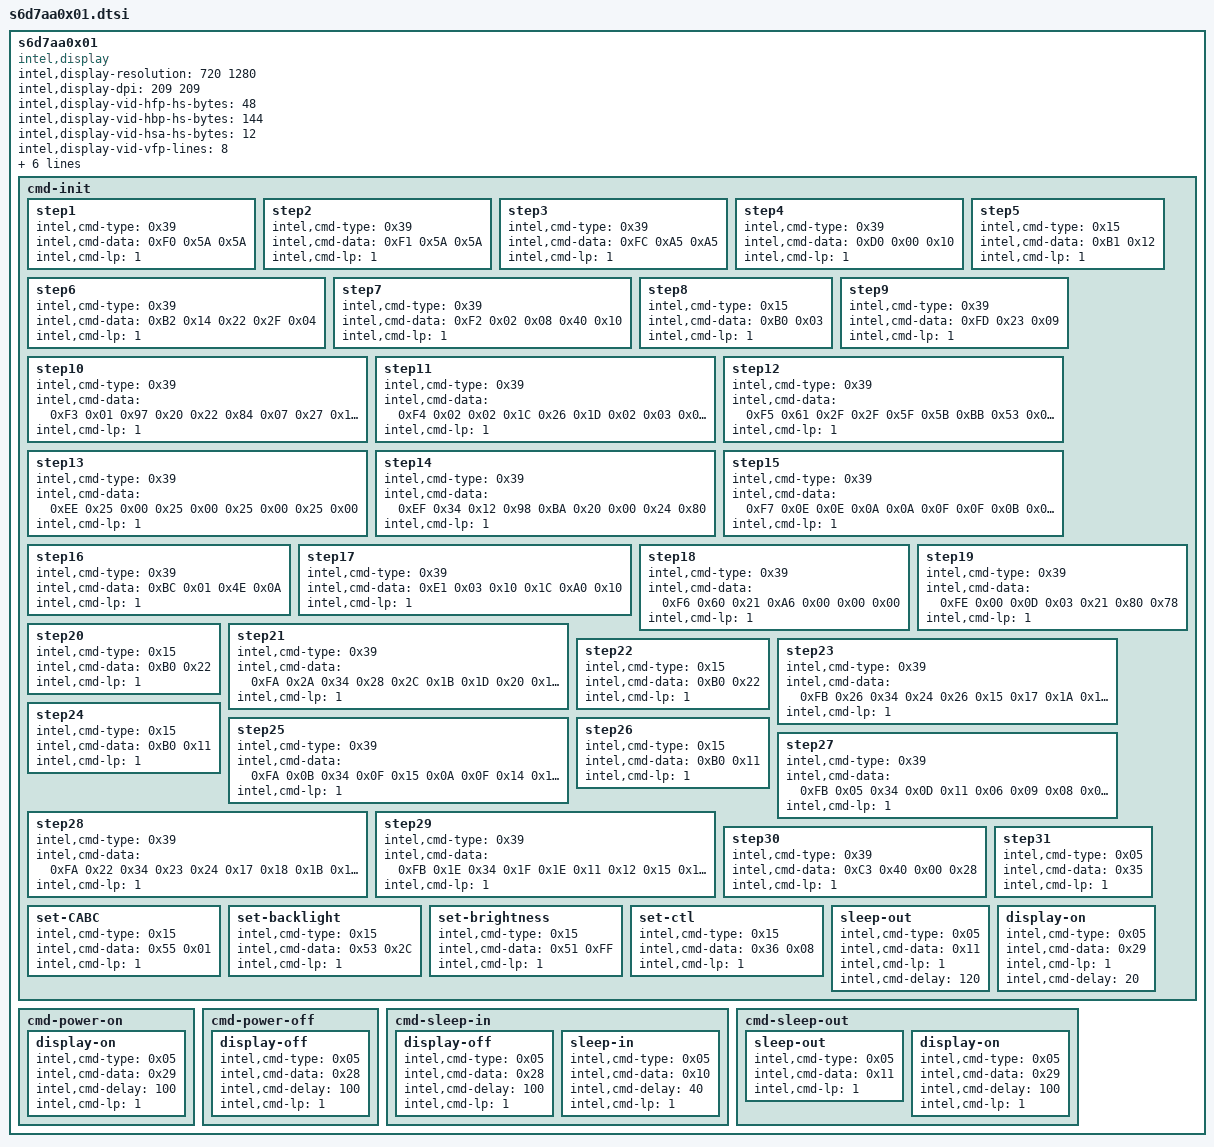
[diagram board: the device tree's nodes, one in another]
s6d7aa0x01{
		compatible = "intel,display";
		intel,display-resolution= <720 1280>;
		intel,display-dpi= <209 209>;

		/* MIPI-DSI video mode settings */
		intel,display-vid-hfp-hs-bytes = <48>;
		intel,display-vid-hbp-hs-bytes = <144>;
		intel,display-vid-hsa-hs-bytes = <12>;
		intel,display-vid-vfp-lines = <8>;
		intel,display-vid-vbp-lines = <4>;
		intel,display-vid-vsa-lines = <4>;

		intel,display-vid-mode = "burst";
		intel,display-vid-id = <0>;
		intel,display-vid-pixel = "24packed";

		intel,display-reset = <1 2 0 1 1 20>;

		cmd-init {
			step1 {
				intel,cmd-type = <0x39>;
				intel,cmd-data = <0xF0 0x5A 0x5A>;
				intel,cmd-lp = <1>;
			};
			step2{
				intel,cmd-type = <0x39>;
				intel,cmd-data = <0xF1 0x5A 0x5A>;
				intel,cmd-lp = <1>;
			};
			step3 {
				intel,cmd-type = <0x39>;
				intel,cmd-data = <0xFC 0xA5 0xA5>;
				intel,cmd-lp = <1>;
			};
			step4 {
				intel,cmd-type = <0x39>;
				intel,cmd-data = <0xD0 0x00 0x10>;
				intel,cmd-lp = <1>;
			};
			step5 {
				intel,cmd-type = <0x15>;
				intel,cmd-data = <0xB1 0x12>;
				intel,cmd-lp = <1>;
			};
			step6 {
				intel,cmd-type = <0x39>;
				intel,cmd-data = <0xB2 0x14 0x22 0x2F 0x04>;
				intel,cmd-lp = <1>;
			};
			step7 {
				intel,cmd-type = <0x39>;
				intel,cmd-data = <0xF2 0x02 0x08 0x40 0x10>;
				intel,cmd-lp = <1>;
			};
			step8 {
				intel,cmd-type = <0x15>;
				intel,cmd-data = <0xB0 0x03>;
				intel,cmd-lp = <1>;
			};
			step9 {
				intel,cmd-type = <0x39>;
				intel,cmd-data = <0xFD 0x23 0x09>;
				intel,cmd-lp = <1>;
			};
			step10 {
				intel,cmd-type = <0x39>;
				intel,cmd-data = <0xF3 0x01 0x97 0x20 0x22 0x84 0x07 0x27 0x10 0x26 0x00>;
				intel,cmd-lp = <1>;
			};
			step11 {
				intel,cmd-type = <0x39>;
				intel,cmd-data = <0xF4 0x02 0x02 0x1C 0x26 0x1D 0x02 0x03 0x03 0x03 0x1C 0x01C 0x03 0x00 0x0C 0x0C 0x03 0x02 0x03 0x06 0x06 0x13 0x14 0x01 0x15 0x01 0x04 0x02 0x61 0x78 0x79 0x72 0xE3 0xF3 0xF0 0x00 0x00 0x01 0x01 0x28 0x04 0x03 0x28 0x01 0xD1 0x32>;
				intel,cmd-lp = <1>;
			};
			step12 {
				intel,cmd-type = <0x39>;
				intel,cmd-data = <0xF5 0x61 0x2F 0x2F 0x5F 0x5B 0xBB 0x53 0x0F 0x33 0x23 0x02 0x59 0x54 0x52 0x45 0x46 0x60 0x02 0x60 0x80 0x27 0x26 0x52 0x25 0x7A 0x1F>;
				intel,cmd-lp = <1>;
			};
			step13 {
				intel,cmd-type = <0x39>;
				intel,cmd-data = <0xEE 0x25 0x00 0x25 0x00 0x25 0x00 0x25 0x00>;
				intel,cmd-lp = <1>;
			};
			step14 {
				intel,cmd-type = <0x39>;
				intel,cmd-data = <0xEF 0x34 0x12 0x98 0xBA 0x20 0x00 0x24 0x80>;
				intel,cmd-lp = <1>;
			};
			step15 {
				intel,cmd-type = <0x39>;
				intel,cmd-data = <0xF7 0x0E 0x0E 0x0A 0x0A 0x0F 0x0F 0x0B 0x0B 0x05 0x07 0x01 0x01 0x01 0x01 0x01 0x01 0x0C 0x0C 0x08 0x08 0x0D 0x0D 0x09 0x09 0x04 0x06 0x01 0x01 0x01 0x01 0x01 0x01 >;
				intel,cmd-lp = <1>;
			};
			step16 {
				intel,cmd-type = <0x39>;
				intel,cmd-data = <0xBC 0x01 0x4E 0x0A >;
				intel,cmd-lp = <1>;
			};
			step17 {
				intel,cmd-type = <0x39>;
				intel,cmd-data = <0xE1 0x03 0x10 0x1C 0xA0 0x10 >;
				intel,cmd-lp = <1>;
			};
			step18 {
				intel,cmd-type = <0x39>;
				intel,cmd-data = <0xF6 0x60 0x21 0xA6 0x00 0x00 0x00>;
				intel,cmd-lp = <1>;
			};
			step19 {
				intel,cmd-type = <0x39>;
				intel,cmd-data = <0xFE 0x00 0x0D 0x03 0x21 0x80 0x78>;
				intel,cmd-lp = <1>;
			};
			/*	T=7000, duv =0.0045, and IS
				255  252    239   223   183    71    31    15    3
     				0    248    231   215   127   39    23    7	*/
			step20 {
				intel,cmd-type = <0x15>;
				intel,cmd-data = <0xB0 0x22>;
				intel,cmd-lp = <1>;
			};
			step21 {
				intel,cmd-type = <0x39>;
				intel,cmd-data = <0xFA 0x2A 0x34 0x28 0x2C 0x1B 0x1D 0x20 0x1C 0x1A 0x1F 0x21 0x20 0x20 0x1F 0x20 0x22 0x2A>;
				intel,cmd-lp = <1>;
			};
			step22 {
				intel,cmd-type = <0x15>;
				intel,cmd-data = <0xB0 0x22>;
				intel,cmd-lp = <1>;
			};
			step23 {
				intel,cmd-type = <0x39>;
				intel,cmd-data = <0xFB 0x26 0x34 0x24 0x26 0x15 0x17 0x1A 0x19 0x16 0x1B 0x1F 0x1E 0x20 0x1F 0x20 0x22 0x2A>;
				intel,cmd-lp = <1>;
			};
			step24 {
				intel,cmd-type = <0x15>;
				intel,cmd-data = <0xB0 0x11>;
				intel,cmd-lp = <1>;
			};
			step25 {
				intel,cmd-type = <0x39>;
				intel,cmd-data = <0xFA 0x0B 0x34 0x0F 0x15 0x0A 0x0F 0x14 0x12 0x13 0x1C 0x1F 0x1E 0x1E 0x1D 0x1C 0x18 0x1D>;
				intel,cmd-lp = <1>;
			};
			step26 {
				intel,cmd-type = <0x15>;
				intel,cmd-data = <0xB0 0x11>;
				intel,cmd-lp = <1>;
			};
			step27 {
				intel,cmd-type = <0x39>;
				intel,cmd-data = <0xFB 0x05 0x34 0x0D 0x11 0x06 0x09 0x08 0x0E 0x0F 0x18 0x1D 0x1C 0x1E 0x1D 0x1C 0x17 0x1F>;
				intel,cmd-lp = <1>;
			};
			step28 {
				intel,cmd-type = <0x39>;
				intel,cmd-data = <0xFA 0x22 0x34 0x23 0x24 0x17 0x18 0x1B 0x18 0x16 0x1E 0x20 0x20 0x21 0x21 0x21 0x22 0x2A>;
				intel,cmd-lp = <1>;
			};
			step29 {
				intel,cmd-type = <0x39>;
				intel,cmd-data = <0xFB 0x1E 0x34 0x1F 0x1E 0x11 0x12 0x15 0x14 0x12 0x1A 0x21 0x1E 0x20 0x21 0x21 0x21 0x2A>;
				intel,cmd-lp = <1>;
			};
			step30 {
				intel,cmd-type = <0x39>;
				intel,cmd-data = <0xC3 0x40 0x00 0x28>;
				intel,cmd-lp = <1>;
			};
			step31 {
				intel,cmd-type = <0x05>;
				intel,cmd-data = <0x35>;
				intel,cmd-lp = <1>;
			};
			set-CABC {
				intel,cmd-type = <0x15>;
				intel,cmd-data = <0x55 0x01>;
				intel,cmd-lp = <1>;
			};
			set-backlight {
				intel,cmd-type = <0x15>;
				intel,cmd-data = <0x53 0x2C>;
				intel,cmd-lp = <1>;
			};
		  	set-brightness {
				intel,cmd-type = <0x15>;
				intel,cmd-data = <0x51 0xFF>;
				intel,cmd-lp = <1>;
			};
			set-ctl {
				intel,cmd-type = <0x15>;
				intel,cmd-data = <0x36 0x08>;
				intel,cmd-lp = <1>;
			};
			sleep-out {
				intel,cmd-type = <0x05>;
				intel,cmd-data = <0x11>;
				intel,cmd-lp = <1>;
				intel,cmd-delay = <120>;
			};
			display-on{
				intel,cmd-type = <0x05>;
				intel,cmd-data = <0x29>;
				intel,cmd-lp = <1>;
				intel,cmd-delay = <20>;
			};
		};
		cmd-power-on {
			display-on{
				intel,cmd-type = <0x05>;
				intel,cmd-data = <0x29>;
				intel,cmd-delay = <100>;
				intel,cmd-lp = <1>;
			};
		};

		cmd-power-off {
			display-off{
				intel,cmd-type = <0x05>;
				intel,cmd-data = <0x28>;
				intel,cmd-delay = <100>;
				intel,cmd-lp = <1>;
			};
		};

		cmd-sleep-in {
			display-off{
				intel,cmd-type = <0x05>;
				intel,cmd-data = <0x28>;
				intel,cmd-delay = <100>;
				intel,cmd-lp = <1>;
			};
			sleep-in{
				intel,cmd-type = <0x05>;
				intel,cmd-data = <0x10>;
				intel,cmd-delay = <40>;
				intel,cmd-lp = <1>;
			};
		};

		cmd-sleep-out {
			sleep-out{
				intel,cmd-type = <0x05>;
				intel,cmd-data = <0x11>;
				intel,cmd-lp = <1>;
			};
			display-on{
				intel,cmd-type = <0x05>;
				intel,cmd-data = <0x29>;
				intel,cmd-delay = <100>;
				intel,cmd-lp = <1>;
			};
		};
};
